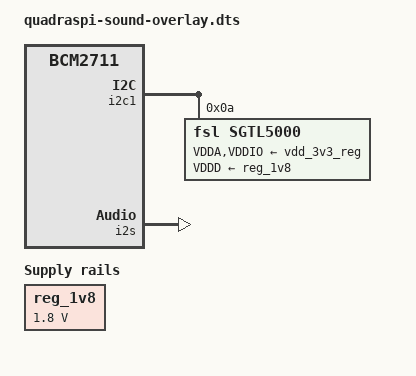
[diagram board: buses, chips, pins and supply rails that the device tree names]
/*
 * Devicetree overlay for sgtl5000 sound chip
 */

 /dts-v1/;
 /plugin/;

 #include <dt-bindings/pinctrl/bcm2835.h>
 #include <dt-bindings/clock/bcm2835.h>
 #include <dt-bindings/gpio/gpio.h>

 /{
     compatible = "brcm,bcm2711";

     fragment@0 {
         target = <&gpio>;
         __overlay__ {
             gpclk2_pin: gpclk2_pin {
                 brcm,pins = <6>;
                 brcm,function = <4>;
             };

             pcm_pins: pcm_pins {
                 brcm,pins = <18 19 20 21>;
                 brcm,function = <4 4 4 4>;
             };
         };
     };

     fragment@1 {
         target = <&soc>;
         __overlay__ {
             reg_1v8: reg_1v8@0 {
                 compatible = "regulator-fixed";
                 regulator-name = "1v8";
                 regulator-min-microvolt = <1800000>;
                 regulator-max-microvolt = <1800000>;
                 regulator-always-on;
             };
         };
     };

     fragment@2 {
         target = <&i2c1>;
         __overlay__ {
             /* needed to avoid dtc warning */
             #address-cells = <1>;
             #size-cells = <0>;
             status = "okay";

             sgtl5000: sgtl5000 {
                 #sound-dai-cells = <0>;
                 compatible = "fsl,sgtl5000";
                 reg = <0x0a>;

                 pinctrl-names = "default";
                 pinctrl-0 = <&gpclk2_pin>;
                 clocks = <&clocks BCM2835_CLOCK_GP2>;
                 clock-names = "mclk";
                 assigned-clocks = <&clocks BCM2835_CLOCK_GP2>;
                 assigned-clock-rates = <12288000>;

                 micbias-resistor-k-ohms = <2>;
                 micbias-voltage-m-volts = <3000>;
                 VDDA-supply = <&vdd_3v3_reg>;
                 VDDIO-supply = <&vdd_3v3_reg>;
                 VDDD-supply = <&reg_1v8>;
                 status = "okay";
             };
         };
     };

     fragment@3 {
         target = <&i2s>;
         __overlay__ {
             clocks = <&clocks BCM2835_CLOCK_PCM>;
             clock-names = "pcm";

             pinctrl-names = "default";
             pinctrl-0 = <&pcm_pins>;
             status = "okay";
         };
     };

     fragment@4 {
         target = <&sound>;
         __overlay__ {
            compatible = "simple-audio-card";
             i2s-controller = <&i2s>;
             status = "okay";


             simple-audio-card,name = "QuadrasPi SGTL5000";
             simple-audio-card,format = "i2s";

             simple-audio-card,bitclock-master = <&soundmaster>;
             simple-audio-card,frame-master = <&soundmaster>;

             simple-audio-card,widgets =
                 "Microphone", "Microphone Jack",
                 "Line", "Line In Jack",
                 "Headphone", "Headphone Jack",
                 "Speaker", "External Speaker";
             simple-audio-card,routing =
                 "MIC_IN", "Microphone Jack",
                 "LINE_IN", "Line In Jack",
                 "Headphone Jack", "HP_OUT",
                 "External Speaker", "LINE_OUT";


             dailink0_master: simple-audio-card,cpu {
                 sound-dai = <&i2s>;
             };

             soundmaster: simple-audio-card,codec {
                 sound-dai = <&sgtl5000>;
                 system-clock-frequency = <12288000>;
             };
         };
     };
};
